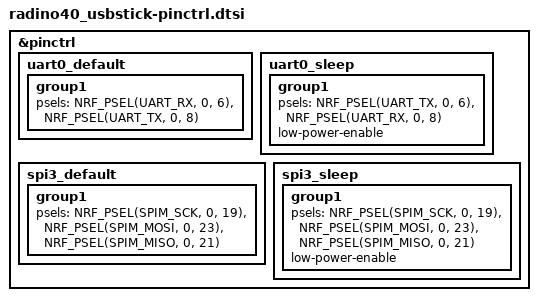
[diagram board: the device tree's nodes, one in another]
/*
 * SPDX-License-Identifier: Apache-2.0
 */

&pinctrl {
	uart0_default: uart0_default {
		group1 {
			psels = <NRF_PSEL(UART_RX, 0, 6)>,
				<NRF_PSEL(UART_TX, 0, 8)>;
		};
	};

	uart0_sleep: uart0_sleep {
		group1 {
			psels = <NRF_PSEL(UART_TX, 0, 6)>,
				<NRF_PSEL(UART_RX, 0, 8)>;
			low-power-enable;
		};
	};

	spi3_default: spi3_default {
		group1 {
			psels = <NRF_PSEL(SPIM_SCK, 0, 19)>,
				<NRF_PSEL(SPIM_MOSI, 0, 23)>,
				<NRF_PSEL(SPIM_MISO, 0, 21)>;
		};
	};

	spi3_sleep: spi3_sleep {
		group1 {
			psels = <NRF_PSEL(SPIM_SCK, 0, 19)>,
				<NRF_PSEL(SPIM_MOSI, 0, 23)>,
				<NRF_PSEL(SPIM_MISO, 0, 21)>;
			low-power-enable;
		};
	};
};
